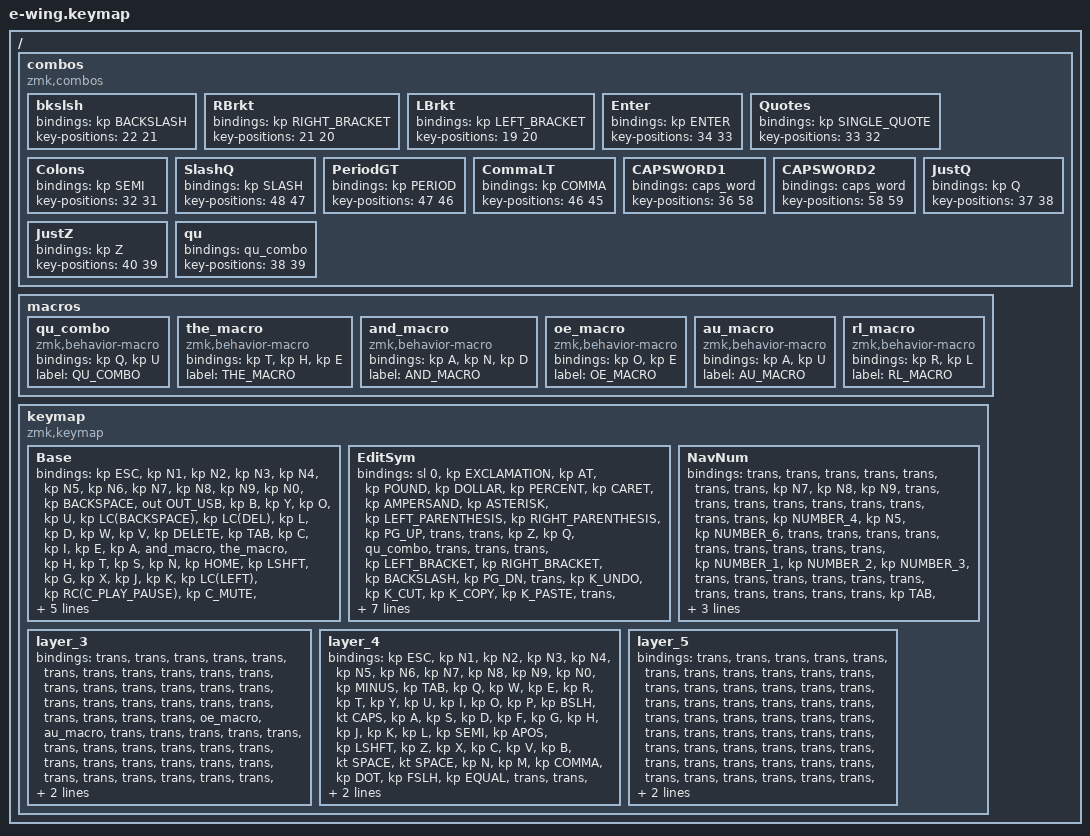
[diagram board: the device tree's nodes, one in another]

#if 1
/*
 * Copyright (c) 2020 The ZMK Contributors
 *
 * SPDX-License-Identifier: MIT
 */

#include <behaviors.dtsi>
#include <dt-bindings/zmk/keys.h>
//#include <dt-bindings/zmk/keys.h>
#include <dt-bindings/zmk/outputs.h>
/ {
    combos {
        compatible = "zmk,combos";

        bkslsh {
            bindings = <&kp BACKSLASH>;
            key-positions = <22 21>;
        };

        RBrkt {
            bindings = <&kp RIGHT_BRACKET>;
            key-positions = <21 20>;
        };

        LBrkt {
            bindings = <&kp LEFT_BRACKET>;
            key-positions = <19 20>;
        };

        Enter {
            bindings = <&kp ENTER>;
            key-positions = <34 33>;
        };

        Quotes {
            bindings = <&kp SINGLE_QUOTE>;
            key-positions = <33 32>;
        };

        Colons {
            bindings = <&kp SEMI>;
            key-positions = <32 31>;
        };

        SlashQ {
            bindings = <&kp SLASH>;
            key-positions = <48 47>;
        };

        PeriodGT {
            bindings = <&kp PERIOD>;
            key-positions = <47 46>;
        };

        CommaLT {
            bindings = <&kp COMMA>;
            key-positions = <46 45>;
        };

        CAPSWORD1 {
            bindings = <&caps_word>;
            key-positions = <36 58>;
        };

        CAPSWORD2 {
            bindings = <&caps_word>;
            key-positions = <58 59>;
        };

        JustQ {
            bindings = <&kp Q>;
            key-positions = <37 38>;
        };

        JustZ {
            bindings = <&kp Z>;
            key-positions = <40 39>;
        };

        qu {
            bindings = <&qu_combo>;
            key-positions = <38 39>;
        };
    };

    macros {
        qu_combo: qu_combo {
            compatible = "zmk,behavior-macro";
            #binding-cells = <0>;
            bindings = <&kp Q &kp U>;
            label = "QU_COMBO";
        };

        the_macro: the_macro {
            compatible = "zmk,behavior-macro";
            #binding-cells = <0>;
            bindings = <&kp T &kp H &kp E>;
            label = "THE_MACRO";
        };

        and_macro: and_macro {
            compatible = "zmk,behavior-macro";
            #binding-cells = <0>;
            bindings = <&kp A &kp N &kp D>;
            label = "AND_MACRO";
        };

        oe_macro: oe_macro {
            compatible = "zmk,behavior-macro";
            #binding-cells = <0>;
            bindings = <&kp O &kp E>;
            label = "OE_MACRO";
        };

        au_macro: au_macro {
            compatible = "zmk,behavior-macro";
            #binding-cells = <0>;
            bindings = <&kp A &kp U>;
            label = "AU_MACRO";
        };

        rl_macro: rl_macro {
            compatible = "zmk,behavior-macro";
            #binding-cells = <0>;
            bindings = <&kp R &kp L>;
            label = "RL_MACRO";
        };
    };

    keymap {
        compatible = "zmk,keymap";

        Base {
            // ------------------------------------------------------------------------------------------------------------
            // |  ESC  |  1  |  2  |  3   |  4   |  5   |                   |  6   |  7    |  8    |  9   |   0   |   -   |
            // |  TAB  |  Q  |  W  |  E   |  R   |  T   |                   |  Y   |  U    |  I    |  O   |   P   |   \   |
            // |  CTRL |  A  |  S  |  D   |  F   |  G   |                   |  H   |  J    |  K    |  L   |   ;   |   '   |
            // | SHIFT |  Z  |  X  |  C   |  V   |  B   |                   |  N   |  M    |  ,    |  .   |   /   | SHIFT |
            // | LCTL  | LGUI  | LALT |  GRAV |  | EQL | DEL | BKSP|  | RET | SPC  | LBKT |  RBKT  | LBKT | HOME  |   END |

            bindings = <
&kp ESC  &kp N1  &kp N2  &kp N3  &kp N4  &kp N5  &kp N6  &kp N7  &kp N8  &kp N9  &kp N0  &kp BACKSPACE  &out OUT_USB  &kp B  &kp Y  &kp O  &kp U  &kp LC(BACKSPACE)  &kp LC(DEL)  &kp L  &kp D  &kp W  &kp V  &kp DELETE  &kp TAB  &kp C  &kp I  &kp E  &kp A  &and_macro  &the_macro  &kp H  &kp T  &kp S  &kp N  &kp HOME  &kp LSHFT  &kp G  &kp X  &kp J  &kp K  &kp LC(LEFT)  &kp RC(C_PLAY_PAUSE)  &kp C_MUTE  &kp RC(RIGHT)  &kp R  &kp M  &kp F  &kp P  &kp END  &sk LCTRL  &sl 1  &sk LALT  &kp RIGHT_ALT  &mo 4  &kp RIGHT_CONTROL  &mo 2  &mo 1  &sk RSHFT  &sk RIGHT_SHIFT  &kp SPACE  &kp RET
            >;
        };

        EditSym {
            bindings = <
&sl 0  &kp EXCLAMATION  &kp AT  &kp POUND  &kp DOLLAR  &kp PERCENT  &kp CARET  &kp AMPERSAND  &kp ASTERISK  &kp LEFT_PARENTHESIS  &kp RIGHT_PARENTHESIS  &kp PG_UP  &trans  &trans  &kp Z  &kp Q  &qu_combo  &trans  &trans  &trans  &kp LEFT_BRACKET  &kp RIGHT_BRACKET  &kp BACKSLASH  &kp PG_DN  &trans  &kp K_UNDO  &kp K_CUT  &kp K_COPY  &kp K_PASTE  &trans  &trans  &trans  &kp SEMICOLON  &kp SINGLE_QUOTE  &kp ENTER  &trans  &trans  &kp K_REDO  &trans  &oe_macro  &au_macro  &trans  &trans  &trans  &trans  &trans  &kp COMMA  &kp PERIOD  &kp SLASH  &trans  &trans  &trans  &trans  &trans  &trans  &trans  &trans  &trans  &trans  &trans  &trans  &trans
            >;
        };

        NavNum {
            bindings = <
&trans  &trans  &trans  &trans  &trans  &trans  &trans  &kp N7  &kp N8  &kp N9  &trans  &trans  &trans  &trans  &trans  &trans  &trans  &trans  &trans  &kp NUMBER_4  &kp N5  &kp NUMBER_6  &trans  &trans  &trans  &trans  &trans  &trans  &trans  &trans  &trans  &kp NUMBER_1  &kp NUMBER_2  &kp NUMBER_3  &trans  &trans  &trans  &trans  &trans  &trans  &trans  &trans  &trans  &trans  &trans  &kp TAB  &kp N0  &kp PERIOD  &trans  &trans  &trans  &trans  &trans  &trans  &trans  &trans  &trans  &trans  &trans  &trans  &trans  &trans
            >;
        };

        layer_3 {
            bindings = <
&trans  &trans  &trans  &trans  &trans  &trans  &trans  &trans  &trans  &trans  &trans  &trans  &trans  &trans  &trans  &trans  &trans  &trans  &trans  &trans  &trans  &trans  &trans  &trans  &trans  &trans  &trans  &oe_macro  &au_macro  &trans  &trans  &trans  &trans  &trans  &trans  &trans  &trans  &trans  &trans  &trans  &trans  &trans  &trans  &trans  &trans  &trans  &trans  &trans  &trans  &trans  &trans  &trans  &trans  &trans  &trans  &trans  &trans  &trans  &trans  &trans  &trans  &trans
            >;
        };

        layer_4 {
            bindings = <
&kp ESC  &kp N1  &kp N2  &kp N3  &kp N4  &kp N5  &kp N6  &kp N7  &kp N8  &kp N9  &kp N0  &kp MINUS  &kp TAB  &kp Q  &kp W  &kp E  &kp R  &kp T  &kp Y  &kp U  &kp I  &kp O  &kp P  &kp BSLH  &kt CAPS  &kp A  &kp S  &kp D  &kp F  &kp G  &kp H  &kp J  &kp K  &kp L  &kp SEMI  &kp APOS  &kp LSHFT  &kp Z  &kp X  &kp C  &kp V  &kp B  &kt SPACE  &kt SPACE  &kp N  &kp M  &kp COMMA  &kp DOT  &kp FSLH  &kp EQUAL  &trans  &trans  &trans  &trans  &trans  &trans  &trans  &trans  &trans  &trans  &trans  &trans
            >;
        };

        layer_5 {
            bindings = <
&trans  &trans  &trans  &trans  &trans  &trans  &trans  &trans  &trans  &trans  &trans  &trans  &trans  &trans  &trans  &trans  &trans  &trans  &trans  &trans  &trans  &trans  &trans  &trans  &trans  &trans  &trans  &trans  &trans  &trans  &trans  &trans  &trans  &trans  &trans  &trans  &trans  &trans  &trans  &trans  &trans  &trans  &trans  &trans  &trans  &trans  &trans  &trans  &trans  &trans  &trans  &trans  &trans  &trans  &trans  &trans  &trans  &trans  &trans  &trans  &trans  &trans
            >;
        };
    };
};
/*&out OUT_USB*/
#endif
